# RS1xxxx register map
Vendor: Silicon Lab Inc.; Series: ARMCM4; File version: 1.2
CPU: CM4 r1p0, little endian, MPU, FPU, 6 interrupt priority bits
Registers are 32-bit, read-write, reset 0x0 unless marked. A register's access mark holds for its fields unless they carry their own. Offsets are from the block's base; [hi:lo] are bit positions; {n}, {i} and the like mark numbered series; 'fields as' and 'values as' point back to an identical list.

## OPAMP — The opamps top consists of 3 general purpose Operational Amplifiers (OPAMP) offering rail-to-rail inputs and outputs
Base 0x24043A14
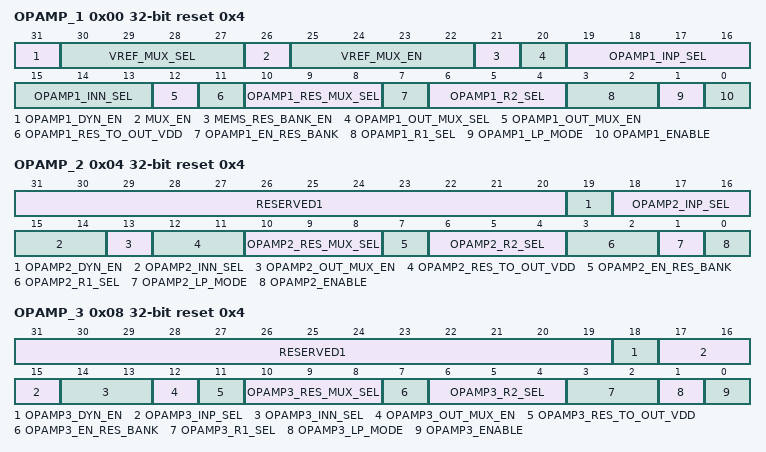
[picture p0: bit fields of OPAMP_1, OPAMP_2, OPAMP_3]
0x00 OPAMP_1 reset 0x4 — Programs opamp1
  [31] OPAMP1_DYN_EN — dynamic enable for opamp1
    0=Disable the opamp1 dynamic mode; 1=Enable the opamp1 dynamic mode
  [30:27] VREF_MUX_SEL — vref mux enable
  [26] MUX_EN — Mux Enable
  [25:22] VREF_MUX_EN — vref mux enable
  [21] MEMS_RES_BANK_EN — enables mems res bank
    0=Disable the memory register bank; 1=Enable the memory register bank
  [20] OPAMP1_OUT_MUX_SEL — to connect opamp1 output to pad
    0=Dis select opamp1 out mux; 1=Select opamp1 out mux
  [19:16] OPAMP1_INP_SEL — selecting +ve input of opamp
    {v}=Input{v}_positive (External pin{v} as positive input for OPAMP1) (v=0..5); 6=DAC (DAC as positive input for OPAMP1); 7=res_tap (register tap as positive input for OPAMP1); 8=opamp1_out as positive input for OPAMP1
  [15:13] OPAMP1_INN_SEL — selecting -ve input of opamp
    0=Input0_Negative (External pin0 as negative input for OPAMP1); 1=Input1_Negative (External pin1 as negative input for OPAMP1); 2=DAC (DAC as negative input for OPAMP1); 3=res_tap (register tap as negative input for OPAMP1); 4=opamp1_out as negative input for OPAMP1
  [12] OPAMP1_OUT_MUX_EN — out mux enable
    0=Disable opamp1 out mux; 1=Enable opamp1 out mux
  [11] OPAMP1_RES_TO_OUT_VDD — connect resistor bank to out or vdd i.e 0-out and 1-vdd
    0=res_out (connect resister bank to out); 1=res_vdd (connect resbank to vdd)
  [10:8] OPAMP1_RES_MUX_SEL — selecting input for registor bank
  [7] OPAMP1_EN_RES_BANK — enables the resistor bank 1 for enable 0 for disable
    0=Disable opamp1 resister bank; 1=Enable opamp1 resister bank
  [6:4] OPAMP1_R2_SEL — Programmability to select resister bank R2
    0=Twenty_ohm (R2 as Twenty_ohm); 1=Thirty_ohm (R1 as Thirty_ohm); 2=forty_ohm (R1 as forty_ohm); 3=Sixty_ohm (R1 as Sixty_ohm); 4=Onetwenty_ohm (R1 as Onetwenty_ohm); 5=twofifty_ohm (R1 as twofifty_ohm); 6=fivehundred_ohm (R1 as fivehundred_ohm); 7=Onethousand_ohm (R1 as Onethousand_ohm)
  [3:2] OPAMP1_R1_SEL — Programmability to select resister bank R1
    0=Zero_ohm (R1 as short); 1=Twenty_ohm (R1 as Twenty_ohm); 2=Sixty_ohm (R1 as Sixty_ohm); 3=Oneforty_ohm (R1 as Oneforty_ohm)
  [1] OPAMP1_LP_MODE — Enable or disable low power mode
    0=Disable opamp1 low power mode; 1=Enable opamp1 low power mode
  [0] OPAMP1_ENABLE — To enable opamp 1
    0=Disable opamp1; 1=Enable opamp1
0x04 OPAMP_2 reset 0x4 — Programs opamp2
  [31:20] RESERVED1 — res
  [19] OPAMP2_DYN_EN — dynamic enable for opamp2
    0=Disable the opamp2 dynamic mode; 1=Enable the opamp2 dynamic mode
  [18:16] OPAMP2_INP_SEL — selecting +ve input of opamp2
    0=Input0_Positive (External pin0 as positive input for OPAMP2); 1=Input1_Positive (External pin1 as positive input for OPAMP2); 2=Input2_Positive (External pin2 as positive input for OPAMP2); 3=DAC (DAC as positive input for OPAMP2); 4=res_tap (register tap as positive input for OPAMP2); 5=gnd (ground as positive input for OPAMP2); 6=OPAMP1_out as positive input for OPAMP2
  [15:14] OPAMP2_INN_SEL — selecting -ve input of opamp
    0=Input0_Negative (External pin0 as negative input for OPAMP2); 1=DAC (DAC as negative input for OPAMP2); 2=res_tap (register tap as negative input for OPAMP2); 3=opamp1_out as negative input for OPAMP2
  [13] OPAMP2_OUT_MUX_EN — out mux enable
    0=Disable opamp2 out mux; 1=Enable opamp2 out mux
  [12:11] OPAMP2_RES_TO_OUT_VDD — connect resistor bank to out or vdd or gnd or DAC i.e 0-out and 1-vdd 2-DAC 3-gnd
    0=resbank_out (connect resbank to out); 1=resbank_vdd (connect resbank to vdd); 2=resbank_DAC (connect resbank to DAC); 3=resbank_GND (connect resbank to gnd)
  [10:8] OPAMP2_RES_MUX_SEL — selecting input for registor bank
  [7] OPAMP2_EN_RES_BANK — enables the resistor bank 1 for enable 0 for disable
    0=Disable opamp2 resister bank; 1=Enable opamp2 resister bank
  [6:4] OPAMP2_R2_SEL — Programmability to select resister bank R2
    values as OPAMP_1.OPAMP1_R2_SEL
  [3:2] OPAMP2_R1_SEL — Programmability to select resister bank R1
    values as OPAMP_1.OPAMP1_R1_SEL
  [1] OPAMP2_LP_MODE — select the power mode 0-normal mode and 1-low power mode
    0=Disable opamp2 low power mode; 1=Enable opamp2 low power mode
  [0] OPAMP2_ENABLE — enables the opamp2
    0=Disable opamp2; 1=Enable opamp2
0x08 OPAMP_3 reset 0x4 — Programs opamp3
  [31:19] RESERVED1 — res
  [18] OPAMP3_DYN_EN — dynamic enable for opamp2
    0=Disable the opamp3 dynamic mode; 1=Enable the opamp3 dynamic mode
  [17:15] OPAMP3_INP_SEL — selecting +ve input of opamp
    0=Input0_Positive (External pin0 as positive input for OPAMP3); 1=Input1_Positive (External pin1 as positive input for OPAMP3); 2=DAC (DAC as positive input for OPAMP3); 3=res_tap (register tap as positive input for OPAMP3); 4=gnd (ground as positive input for OPAMP3); 5=OPAMP2_out as positive input for OPAMP3; 6=OPAMP2_restap as positive input for OPAMP3
  [14:13] OPAMP3_INN_SEL — selecting -ve input of opamp
    0=Input0_Negative (External pin0 as negative input for OPAMP3); 1=DAC (DAC as negative input for OPAMP3); 2=res_tap (register tap as negative input for OPAMP3); 3=opamp2_out as negative input for OPAMP3
  [12] OPAMP3_OUT_MUX_EN — out mux enable
    0=Disable opamp3 out mux; 1=Enable opamp3 out mux
  [11] OPAMP3_RES_TO_OUT_VDD — connect resistor bank to out or vdd i.e 0-out and 1-vdd
    values as OPAMP_1.OPAMP1_RES_TO_OUT_VDD
  [10:8] OPAMP3_RES_MUX_SEL — selecting input for registor bank
  [7] OPAMP3_EN_RES_BANK — enables the resistor bank 1 for enable 0 for disable
    0=Disable opamp3 resister bank; 1=Enable opamp3 resister bank
  [6:4] OPAMP3_R2_SEL — Programmability to select resister bank R2
    values as OPAMP_1.OPAMP1_R2_SEL
  [3:2] OPAMP3_R1_SEL — Programmability to select resister bank R1
    values as OPAMP_1.OPAMP1_R1_SEL
  [1] OPAMP3_LP_MODE — select the power mode 0-normal mode and 1-low power mode
    0=Disable opamp3 low power mode; 1=Enable opamp3 low power mode
  [0] OPAMP3_ENABLE — enables the opamp3 1 for enable 0 for disable
    0=Disable opamp3; 1=Enable opamp3
